# CC430F5123 register map
Registers are 16-bit, read-write, reset 0x0 unless marked. A register's access mark holds for its fields unless they carry their own. Offsets are from the block's base; [hi:lo] are bit positions; {n}, {i} and the like mark numbered series.

## DMA
Base 0x00000000
0x500 DMACTL0 — DMA Module Control 0
  [16:12] DMA1TSEL — DMA channel 1 transfer select bit 0
    0=DMA channel 1 transfer select 0: DMA_REQ (sw); 1=DMA channel 1 transfer select 1: Timer0_A (TA0CCR0.IFG); 2=DMA channel 1 transfer select 2: Timer0_A (TA0CCR2.IFG); 3=DMA channel 1 transfer select 3: Timer1_A (TA1CCR0.IFG); 4=DMA channel 1 transfer select 4: Timer1_A (TA1CCR2.IFG); 5=DMA channel 1 transfer select 5: TimerB (TB0CCR0.IFG); 6=DMA channel 1 transfer select 6: TimerB (TB0CCR2.IFG); {v}=DMA channel 1 transfer select {v}: Reserved (v=7..13); 14=DMA channel 1 transfer select 14: RFRXIFG; 15=DMA channel 1 transfer select 15: RFTXIFG; 16=DMA channel 1 transfer select 16: USCIA0 receive; 17=DMA channel 1 transfer select 17: USCIA0 transmit; 18=DMA channel 1 transfer select 18: USCIB0 receive; 19=DMA channel 1 transfer select 19: USCIB0 transmit; {v}=DMA channel 1 transfer select {v}: Reserved (v=20..23); 24=DMA channel 1 transfer select 24: ADC12IFGx; {v}=DMA channel 1 transfer select {v}: Reserved (v=25..28); 29=DMA channel 1 transfer select 29: Multiplier ready; 30=DMA channel 1 transfer select 30: previous DMA channel DMA0IFG; 31=DMA channel 1 transfer select 31: ext. Trigger (DMAE0)
  [8:4] DMA0TSEL — DMA channel 0 transfer select bit 0
    0=DMA channel 0 transfer select 0: DMA_REQ (sw); 1=DMA channel 0 transfer select 1: Timer0_A (TA0CCR0.IFG); 2=DMA channel 0 transfer select 2: Timer0_A (TA0CCR2.IFG); 3=DMA channel 0 transfer select 3: Timer1_A (TA1CCR0.IFG); 4=DMA channel 0 transfer select 4: Timer1_A (TA1CCR2.IFG); 5=DMA channel 0 transfer select 5: TimerB (TB0CCR0.IFG); 6=DMA channel 0 transfer select 6: TimerB (TB0CCR2.IFG); {v}=DMA channel 0 transfer select {v}: Reserved (v=7..13); 14=DMA channel 0 transfer select 14: RFRXIFG; 15=DMA channel 0 transfer select 15: RFTXIFG; 16=DMA channel 0 transfer select 16: USCIA0 receive; 17=DMA channel 0 transfer select 17: USCIA0 transmit; 18=DMA channel 0 transfer select 18: USCIB0 receive; 19=DMA channel 0 transfer select 19: USCIB0 transmit; {v}=DMA channel 0 transfer select {v}: Reserved (v=20..23); 24=DMA channel 0 transfer select 24: ADC12IFGx; {v}=DMA channel 0 transfer select {v}: Reserved (v=25..28); 29=DMA channel 0 transfer select 29: Multiplier ready; 30=DMA channel 0 transfer select 30: previous DMA channel DMA2IFG; 31=DMA channel 0 transfer select 31: ext. Trigger (DMAE0)
0x502 DMACTL1 — DMA Module Control 1
  [8:4] DMA2TSEL — DMA channel 2 transfer select bit 0
    0=DMA channel 2 transfer select 0: DMA_REQ (sw); 1=DMA channel 2 transfer select 1: Timer0_A (TA0CCR0.IFG); 2=DMA channel 2 transfer select 2: Timer0_A (TA0CCR2.IFG); 3=DMA channel 2 transfer select 3: Timer1_A (TA1CCR0.IFG); 4=DMA channel 2 transfer select 4: Timer1_A (TA1CCR2.IFG); 5=DMA channel 2 transfer select 5: TimerB (TB0CCR0.IFG); 6=DMA channel 2 transfer select 6: TimerB (TB0CCR2.IFG); {v}=DMA channel 2 transfer select {v}: Reserved (v=7..13); 14=DMA channel 2 transfer select 14: RFRXIFG; 15=DMA channel 2 transfer select 15: RFTXIFG; 16=DMA channel 2 transfer select 16: USCIA0 receive; 17=DMA channel 2 transfer select 17: USCIA0 transmit; 18=DMA channel 2 transfer select 18: USCIB0 receive; 19=DMA channel 2 transfer select 19: USCIB0 transmit; {v}=DMA channel 2 transfer select {v}: Reserved (v=20..23); 24=DMA channel 2 transfer select 24: ADC12IFGx; {v}=DMA channel 2 transfer select {v}: Reserved (v=25..28); 29=DMA channel 2 transfer select 29: Multiplier ready; 30=DMA channel 2 transfer select 30: previous DMA channel DMA1IFG; 31=DMA channel 2 transfer select 31: ext. Trigger (DMAE0)
0x504 DMACTL2 — DMA Module Control 2
0x506 DMACTL3 — DMA Module Control 3
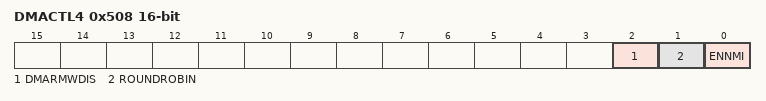
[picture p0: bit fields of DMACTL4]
0x508 DMACTL4 — DMA Module Control 4
  [2] DMARMWDIS — Inhibited DMA transfers during read-modify-write CPU operations
  [1] ROUNDROBIN — Round-Robin DMA channel priorities
  [0] ENNMI — Enable NMI interruption of DMA
0x50E DMAIV — DMA Interrupt Vector Word
{0x510+0x10*i} DMA{i}CTL (i=0..2) — DMA Channel {i} Control
  [16:14] DMADT — DMA transfer mode bit 0
    0=DMA transfer mode 0: Single transfer; 1=DMA transfer mode 1: Block transfer; 2=DMA transfer mode 2: Burst-Block transfer; 3=DMA transfer mode 3: Burst-Block transfer; 4=DMA transfer mode 4: Repeated Single transfer; 5=DMA transfer mode 5: Repeated Block transfer; 6=DMA transfer mode 6: Repeated Burst-Block transfer; 7=DMA transfer mode 7: Repeated Burst-Block transfer
  [12:11] DMADSTINCR — DMA destination increment bit 0
    0=DMA destination increment 0: destination address unchanged; 1=DMA destination increment 1: destination address unchanged; 2=DMA destination increment 2: destination address decremented; 3=DMA destination increment 3: destination address incremented
  [10:9] DMASRCINCR — DMA source increment bit 0
    0=DMA source increment 0: source address unchanged; 1=DMA source increment 1: source address unchanged; 2=DMA source increment 2: source address decremented; 3=DMA source increment 3: source address incremented
  [7] DMADSTBYTE — DMA destination byte
  [6] DMASRCBYTE — DMA source byte
  [5] DMALEVEL — DMA level sensitive trigger select
  [4] DMAEN — DMA enable
  [3] DMAIFG — DMA interrupt flag
  [2] DMAIE — DMA interrupt enable
  [1] DMAABORT — DMA transfer aborted by NMI
  [0] DMAREQ — Initiate DMA transfer with DMATSEL
{0x512+0x10*i} DMA{i}SA 32-bit (i=0..2) — DMA Channel {i} Source Address
{0x516+0x10*i} DMA{i}DA 32-bit (i=0..2) — DMA Channel {i} Destination Address
{0x51A+0x10*i} DMA{i}SZ (i=0..2) — DMA Channel {i} Transfer Size
